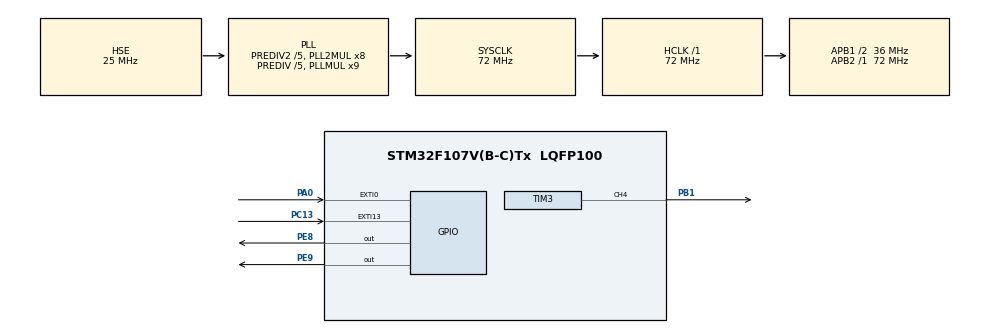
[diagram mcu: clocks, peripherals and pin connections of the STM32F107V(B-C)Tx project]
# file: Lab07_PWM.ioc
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Mcu.Family=STM32F1
Mcu.Name=STM32F107V(B-C)Tx
Mcu.Package=LQFP100
NVIC.EXTI0_IRQn=true\:1\:0\:true\:false\:true\:true
NVIC.EXTI15_10_IRQn=true\:1\:1\:true\:false\:true\:true
NVIC.PriorityGroup=NVIC_PRIORITYGROUP_1
OSC_IN.Mode=HSE-External-Oscillator
OSC_IN.Signal=RCC_OSC_IN
OSC_OUT.Mode=HSE-External-Oscillator
OSC_OUT.Signal=RCC_OSC_OUT
PA0-WKUP.Signal=GPXTI0
PB1.GPIO_Speed=GPIO_SPEED_FREQ_HIGH
PB1.Signal=S_TIM3_CH4
PC13-TAMPER-RTC.Signal=GPXTI13
PE8.GPIO_Speed=GPIO_SPEED_FREQ_HIGH
PE8.Signal=GPIO_Output
PE9.GPIO_Speed=GPIO_SPEED_FREQ_HIGH
PE9.Signal=GPIO_Output
ProjectManager.HeapSize=0x200
ProjectManager.StackSize=0x400
ProjectManager.TargetToolchain=MDK-ARM V5
RCC.AHBFreq_Value=72000000
RCC.APB1CLKDivider=RCC_HCLK_DIV2
RCC.APB1Freq_Value=36000000
RCC.APB1TimFreq_Value=72000000
RCC.APB2Freq_Value=72000000
RCC.APB2TimFreq_Value=72000000
RCC.HCLKFreq_Value=72000000
RCC.HSEDivPLL=RCC_HSE_PREDIV_DIV5
RCC.HSE_VALUE=25000000
RCC.PLLMUL=RCC_PLL_MUL9
RCC.PLLSourceVirtual=RCC_PLLSOURCE_HSE
RCC.Prediv1Source=RCC_PREDIV1_SOURCE_PLL2
RCC.Prediv2=RCC_HSE_PREDIV2_DIV5
RCC.SYSCLKFreq_VALUE=72000000
RCC.SYSCLKSource=RCC_SYSCLKSOURCE_PLLCLK
RCC.USBFreq_Value=48000000
SH.S_TIM3_CH4.0=TIM3_CH4,PWM Generation4 CH4
TIM3.Channel-PWM\ Generation4\ CH4=TIM_CHANNEL_4
TIM3.Period=10000-1
TIM3.Prescaler=720-1
TIM3.Pulse-PWM\ Generation4\ CH4=(10000-1)/2
VP_SYS_VS_ND.Mode=No_Debug
VP_TIM3_VS_ClockSourceINT.Mode=Internal
board=Lab07_PWM

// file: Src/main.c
/**
  ******************************************************************************
  * File Name          : main.c
  * Description        : Main program body
  ******************************************************************************
  ** This notice applies to any and all portions of this file
  * that are not between comment pairs USER CODE BEGIN and
  * USER CODE END. Other portions of this file, whether
  * inserted by the user or by software development tools
  * are owned by their respective copyright owners.
  *
  * COPYRIGHT(c) 2018 STMicroelectronics
  *
  * Redistribution and use in source and binary forms, with or without modification,
  * are permitted provided that the following conditions are met:
  *   1. Redistributions of source code must retain the above copyright notice,
  *      this list of conditions and the following disclaimer.
  *   2. Redistributions in binary form must reproduce the above copyright notice,
  *      this list of conditions and the following disclaimer in the documentation
  *      and/or other materials provided with the distribution.
  *   3. Neither the name of STMicroelectronics nor the names of its contributors
  *      may be used to endorse or promote products derived from this software
  *      without specific prior written permission.
  *
  * THIS SOFTWARE IS PROVIDED BY THE COPYRIGHT HOLDERS AND CONTRIBUTORS "AS IS"
  * AND ANY EXPRESS OR IMPLIED WARRANTIES, INCLUDING, BUT NOT LIMITED TO, THE
  * IMPLIED WARRANTIES OF MERCHANTABILITY AND FITNESS FOR A PARTICULAR PURPOSE ARE
  * DISCLAIMED. IN NO EVENT SHALL THE COPYRIGHT HOLDER OR CONTRIBUTORS BE LIABLE
  * FOR ANY DIRECT, INDIRECT, INCIDENTAL, SPECIAL, EXEMPLARY, OR CONSEQUENTIAL
  * DAMAGES (INCLUDING, BUT NOT LIMITED TO, PROCUREMENT OF SUBSTITUTE GOODS OR
  * SERVICES; LOSS OF USE, DATA, OR PROFITS; OR BUSINESS INTERRUPTION) HOWEVER
  * CAUSED AND ON ANY THEORY OF LIABILITY, WHETHER IN CONTRACT, STRICT LIABILITY,
  * OR TORT (INCLUDING NEGLIGENCE OR OTHERWISE) ARISING IN ANY WAY OUT OF THE USE
  * OF THIS SOFTWARE, EVEN IF ADVISED OF THE POSSIBILITY OF SUCH DAMAGE.
  *
  ******************************************************************************
  */

#include "main.h"
#include "stm32f1xx_hal.h"

TIM_HandleTypeDef htim3;

/* USER CODE BEGIN PV */
/* Private variables ---------------------------------------------------------*/
float dutyCycle = 0.5;
/* USER CODE END PV */

void SystemClock_Config(void);
static void MX_GPIO_Init(void);
static void MX_TIM3_Init(void);
void HAL_TIM_MspPostInit(TIM_HandleTypeDef *htim);

/* USER CODE BEGIN PFP */
/* Private function prototypes -----------------------------------------------*/

/* USER CODE END PFP */

int main(void)
{

  /* MCU Configuration----------------------------------------------------------*/

  /* Reset of all peripherals, Initializes the Flash interface and the Systick. */
  HAL_Init();

  /* Configure the system clock */
  SystemClock_Config();

  /* Initialize all configured peripherals */
  MX_GPIO_Init();
  MX_TIM3_Init();

  /* USER CODE BEGIN 2 */
	GPIOE->ODR = 0x00000200;
  /* USER CODE END 2 */

  /* Infinite loop */
  while (1)
  {

  /* USER CODE BEGIN 3 */
		htim3.Instance->CCR4 = (10000-1)*dutyCycle;

		HAL_TIM_PWM_Start(&htim3, TIM_CHANNEL_4);
		HAL_Delay(100);
		HAL_TIM_PWM_Stop(&htim3, TIM_CHANNEL_4);
  }
  /* USER CODE END 3 */

}

/** System Clock Configuration
*/
void SystemClock_Config(void)
{

  RCC_OscInitTypeDef RCC_OscInitStruct;
  RCC_ClkInitTypeDef RCC_ClkInitStruct;

    /**Initializes the CPU, AHB and APB busses clocks
    */
  RCC_OscInitStruct.OscillatorType = RCC_OSCILLATORTYPE_HSE;
  RCC_OscInitStruct.HSEState = RCC_HSE_ON;
  RCC_OscInitStruct.HSEPredivValue = RCC_HSE_PREDIV_DIV5;
  RCC_OscInitStruct.HSIState = RCC_HSI_ON;
  RCC_OscInitStruct.Prediv1Source = RCC_PREDIV1_SOURCE_PLL2;
  RCC_OscInitStruct.PLL.PLLState = RCC_PLL_ON;
  RCC_OscInitStruct.PLL.PLLSource = RCC_PLLSOURCE_HSE;
  RCC_OscInitStruct.PLL.PLLMUL = RCC_PLL_MUL9;
  RCC_OscInitStruct.PLL2.PLL2State = RCC_PLL2_ON;
  RCC_OscInitStruct.PLL2.PLL2MUL = RCC_PLL2_MUL8;
  RCC_OscInitStruct.PLL2.HSEPrediv2Value = RCC_HSE_PREDIV2_DIV5;
  if (HAL_RCC_OscConfig(&RCC_OscInitStruct) != HAL_OK)
  {
    _Error_Handler(__FILE__, __LINE__);
  }

    /**Initializes the CPU, AHB and APB busses clocks
    */
  RCC_ClkInitStruct.ClockType = RCC_CLOCKTYPE_HCLK|RCC_CLOCKTYPE_SYSCLK
                              |RCC_CLOCKTYPE_PCLK1|RCC_CLOCKTYPE_PCLK2;
  RCC_ClkInitStruct.SYSCLKSource = RCC_SYSCLKSOURCE_PLLCLK;
  RCC_ClkInitStruct.AHBCLKDivider = RCC_SYSCLK_DIV1;
  RCC_ClkInitStruct.APB1CLKDivider = RCC_HCLK_DIV2;
  RCC_ClkInitStruct.APB2CLKDivider = RCC_HCLK_DIV1;

  if (HAL_RCC_ClockConfig(&RCC_ClkInitStruct, FLASH_LATENCY_2) != HAL_OK)
  {
    _Error_Handler(__FILE__, __LINE__);
  }

    /**Configure the Systick interrupt time
    */
  HAL_SYSTICK_Config(HAL_RCC_GetHCLKFreq()/1000);

    /**Configure the Systick
    */
  HAL_SYSTICK_CLKSourceConfig(SYSTICK_CLKSOURCE_HCLK);

    /**Configure the Systick interrupt time
    */
  __HAL_RCC_PLLI2S_ENABLE();

  /* SysTick_IRQn interrupt configuration */
  HAL_NVIC_SetPriority(SysTick_IRQn, 0, 0);
}

/* TIM3 init function */
static void MX_TIM3_Init(void)
{

  TIM_ClockConfigTypeDef sClockSourceConfig;
  TIM_MasterConfigTypeDef sMasterConfig;
  TIM_OC_InitTypeDef sConfigOC;

  htim3.Instance = TIM3;
  htim3.Init.Prescaler = 720-1;
  htim3.Init.CounterMode = TIM_COUNTERMODE_UP;
  htim3.Init.Period = 10000-1;
  htim3.Init.ClockDivision = TIM_CLOCKDIVISION_DIV1;
  htim3.Init.AutoReloadPreload = TIM_AUTORELOAD_PRELOAD_DISABLE;
  if (HAL_TIM_Base_Init(&htim3) != HAL_OK)
  {
    _Error_Handler(__FILE__, __LINE__);
  }

  sClockSourceConfig.ClockSource = TIM_CLOCKSOURCE_INTERNAL;
  if (HAL_TIM_ConfigClockSource(&htim3, &sClockSourceConfig) != HAL_OK)
  {
    _Error_Handler(__FILE__, __LINE__);
  }

  if (HAL_TIM_PWM_Init(&htim3) != HAL_OK)
  {
    _Error_Handler(__FILE__, __LINE__);
  }

  sMasterConfig.MasterOutputTrigger = TIM_TRGO_RESET;
  sMasterConfig.MasterSlaveMode = TIM_MASTERSLAVEMODE_DISABLE;
  if (HAL_TIMEx_MasterConfigSynchronization(&htim3, &sMasterConfig) != HAL_OK)
  {
    _Error_Handler(__FILE__, __LINE__);
  }

  sConfigOC.OCMode = TIM_OCMODE_PWM1;
  sConfigOC.Pulse = (10000-1)/2;
  sConfigOC.OCPolarity = TIM_OCPOLARITY_HIGH;
  sConfigOC.OCFastMode = TIM_OCFAST_DISABLE;
  if (HAL_TIM_PWM_ConfigChannel(&htim3, &sConfigOC, TIM_CHANNEL_4) != HAL_OK)
  {
    _Error_Handler(__FILE__, __LINE__);
  }

  HAL_TIM_MspPostInit(&htim3);

}

/** Configure pins as
        * Analog
        * Input
        * Output
        * EVENT_OUT
        * EXTI
*/
static void MX_GPIO_Init(void)
{

  GPIO_InitTypeDef GPIO_InitStruct;

  /* GPIO Ports Clock Enable */
  __HAL_RCC_GPIOC_CLK_ENABLE();
  __HAL_RCC_GPIOA_CLK_ENABLE();
  __HAL_RCC_GPIOB_CLK_ENABLE();
  __HAL_RCC_GPIOE_CLK_ENABLE();

  /*Configure GPIO pin Output Level */
  HAL_GPIO_WritePin(GPIOE, GPIO_PIN_8|GPIO_PIN_9, GPIO_PIN_RESET);

  /*Configure GPIO pin : PC13 */
  GPIO_InitStruct.Pin = GPIO_PIN_13;
  GPIO_InitStruct.Mode = GPIO_MODE_IT_RISING;
  GPIO_InitStruct.Pull = GPIO_NOPULL;
  HAL_GPIO_Init(GPIOC, &GPIO_InitStruct);

  /*Configure GPIO pin : PA0 */
  GPIO_InitStruct.Pin = GPIO_PIN_0;
  GPIO_InitStruct.Mode = GPIO_MODE_IT_RISING;
  GPIO_InitStruct.Pull = GPIO_NOPULL;
  HAL_GPIO_Init(GPIOA, &GPIO_InitStruct);

  /*Configure GPIO pins : PE8 PE9 */
  GPIO_InitStruct.Pin = GPIO_PIN_8|GPIO_PIN_9;
  GPIO_InitStruct.Mode = GPIO_MODE_OUTPUT_PP;
  GPIO_InitStruct.Speed = GPIO_SPEED_FREQ_HIGH;
  HAL_GPIO_Init(GPIOE, &GPIO_InitStruct);

  /* EXTI interrupt init*/
  HAL_NVIC_SetPriority(EXTI0_IRQn, 1, 0);
  HAL_NVIC_EnableIRQ(EXTI0_IRQn);

  HAL_NVIC_SetPriority(EXTI15_10_IRQn, 1, 1);
  HAL_NVIC_EnableIRQ(EXTI15_10_IRQn);

}

void _Error_Handler(char * file, int line)
{
  while(1)
  {
  }
}

/************************ (C) COPYRIGHT STMicroelectronics *****END OF FILE****/
